# apollo3c register map
Vendor: Ambiq Micro; Series: Apollo; File version: 1.0
Ultra-Low power ARM Cortex-M4 MCU from Ambiq Micro
CPU: CM4 r1p0, little endian, MPU, FPU, 3 interrupt priority bits
Registers are 32-bit, read-write, reset 0x0 unless marked. A register's access mark holds for its fields unless they carry their own. Offsets are from the block's base; lines under a group give offsets from that group; [hi:lo] are bit positions; {n}, {i} and the like mark numbered series; 'fields as' and 'values as' point back to an identical list; <NAME> marks a mode.

## Memory map
0x40000000 RSTGEN size 0xFFFF004 — MCU Reset Generator
0x40004000 CLKGEN size 0x110 — Clock Generator
0x40004200 RTC size 0x110 — Real Time Clock
0x40008000 CTIMER size 0x310 — Counter/Timer
0x4000C000 VCOMP size 0x210 — Voltage Comparator
0x40010000 GPIO size 0x254 — General Purpose IO
0x40011000 APBDMA size 0x44 — APB DMA Register Interfaces
0x40018000 CACHECTRL size 0x240 — Flash Cache Controller
0x4001C000 UART0 size 0x48 — Serial UART
0x4001D000 UART1 size 0x48
0x40020000 MCUCTRL size 0x3DC — MCU Miscellaneous Control Logic
0x40021000 PWRCTRL size 0x30 — PWR Controller Register Bank
0x40024000 WDT size 0x210 — Watchdog Timer
0x40030000 SECURITY size 0x90 — Security Interfaces
0x40080000 SCARD size 0x104 — Serial ISO7816
0x50000000 IOSLAVE size 0x220 — I2C/SPI Slave
0x50004000 IOM0 size 0x414 — IO Peripheral Master
0x50005000 IOM1 size 0x414
0x50006000 IOM2 size 0x414
0x50007000 IOM3 size 0x414
0x50008000 IOM4 size 0x414
0x50009000 IOM5 size 0x414
0x5000C000 BLEIF size 0x414 — BLE Interface
0x50010000 ADC size 0x294 — Analog Digital Converter Control
0x50011000 PDM size 0x294 — PDM Audio
0x50014000 MSPI0 size 0x2C8 — Multibit SPI Master
0x50015000 MSPI1 size 0x2C8
0x50016000 MSPI2 size 0x2C8

## Interrupts
0 BROWNOUT (MCUCTRL)
1 WDT
2 RTC
3 VCOMP
4 IOSLAVE
5 IOSLAVEACC (IOSLAVE)
6 IOMSTR0 (IOM0)
7 IOMSTR1 (IOM1)
8 IOMSTR2 (IOM2)
9 IOMSTR3 (IOM3)
10 IOMSTR4 (IOM4)
11 IOMSTR5 (IOM5)
12 BLE (BLEIF)
13 GPIO
14 CTIMER
15 UART0
16 UART1
17 SCARD
18 ADC
19 PDM
20 MSPI0
22 STIMER (CTIMER)
{n+23} STIMER_CMPR{n} (CTIMER) (n=0..7)
31 CLKGEN
32 MSPI1
33 MSPI2

## APBDMA — APB DMA Register Interfaces
Base 0x40011000
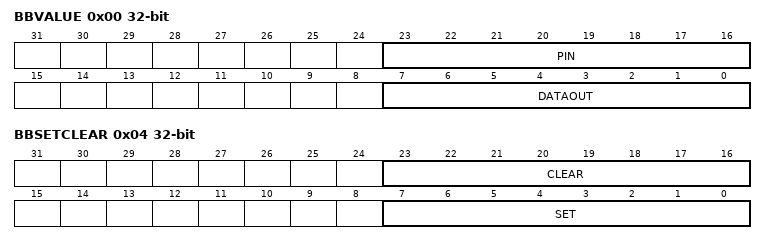
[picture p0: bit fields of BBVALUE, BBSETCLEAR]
0x00 BBVALUE — Control Register
  [23:16] PIN — PIO values
  [7:0] DATAOUT — Data Output Values
0x04 BBSETCLEAR — Set/Clear Register
  [23:16] CLEAR — Write 1 to Clear PIO value
  [7:0] SET — Write 1 to Set PIO value (set hier priority than clear if both bit set)
0x08 BBINPUT — PIO Input Values
  [7:0] DATAIN — PIO values
0x20 DEBUGDATA — PIO Input Values
0x40 DEBUG — PIO Input Values
  [3:0] DEBUGEN — Debug Enable
    0=OFF (Debug Disabled); 1=ARB (Debug Arb values)

## Licence text in the file
Copyright (c) 2019, Ambiq Micro. All rights reserved. . Redistribution and use in source and binary forms, with or without modification, are permitted provided that the following conditions are met: . 1. Redistributions of source code must retain the above copyright notice, this list of conditions and the following disclaimer. . 2. Redistributions in binary form must reproduce the above copyright notice, this list of conditions and the following disclaimer in the documentation and/or other materials provided with the distribution. . 3. Neither the name of the copyright holder nor the names of its contributors may be used to endorse or promote products derived from this software without specific prior written permission. . Third party software included in this distribution is subject to the additional license terms as defined in the /docs/licenses directory. . THIS SOFTWARE IS PROVIDED BY THE COPYRIGHT HOLDERS AND CONTRIBUTORS "AS IS" AND ANY EXPRESS OR IMPLIED WARRANTIES, INCLUDING, BUT NOT LIMITED TO, THE. IMPLIED WARRANTIES OF MERCHANTABILITY AND FITNESS FOR A PARTICULAR PURPOSE. ARE DISCLAIMED. IN NO EVENT SHALL THE COPYRIGHT HOLDER OR CONTRIBUTORS BE. LIABLE FOR ANY DIRECT, INDIRECT, INCIDENTAL, SPECIAL, EXEMPLARY, OR. CONSEQUENTIAL DAMAGES (INCLUDING, BUT NOT LIMITED TO, PROCUREMENT OF. SUBSTITUTE GOODS OR SERVICES; LOSS OF USE, DATA, OR PROFITS; OR BUSINESS. INTERRUPTION) HOWEVER CAUSED AND ON ANY THEORY OF LIABILITY, WHETHER IN. CONTRACT, STRICT LIABILITY, OR TORT (INCLUDING NEGLIGENCE OR OTHERWISE). ARISING IN ANY WAY OUT OF THE USE OF THIS SOFTWARE, EVEN IF ADVISED OF THE. POSSIBILITY OF SUCH DAMAGE.

## Notices in the file
Copyright (C) 2012-2014 ARM Limited. All rights reserved.
Purpose: System Viewer Description (SVD) Example (Schema Version 1.1)
This is a description of a none-existent and incomplete device
for demonstration purposes only.
- Neither the name of ARM nor the names of its contributors may be used
ARE DISCLAIMED. IN NO EVENT SHALL COPYRIGHT HOLDERS AND CONTRIBUTORS BE
